# CY8C5888LTI_LP097 register map
File version: 0.1
CY8C58LP
Registers are 8-bit, read-write, no defined reset value unless marked. A register's access mark holds for its fields unless they carry their own. Offsets are from the block's base; lines under a group give offsets from that group; [hi:lo] are bit positions; {n}, {i} and the like mark numbered series; 'fields as' and 'values as' point back to an identical list; <NAME> marks a mode.

## Memory map
0x00000000 Counter_2
0x00000000 SleepTimer_1
0x00000000 LED_Reset
0x00000000 Control_Reset
0x00000000 Control_Reg_1
0x00000000 Counter_1
0x00000000 Control_Timer_Reset
0x00000000 Timer_1

## Counter_2
Base 0x00000000
0x40006401 Counter_2_COUNTER — UDB.A0 - Current Counter Value
0x40006421 Counter_2_PERIOD — UDB.D0 - Assigned Period
0x40006431 Counter_2_COMPARE — UDB.D1 - Assigned Compare Value
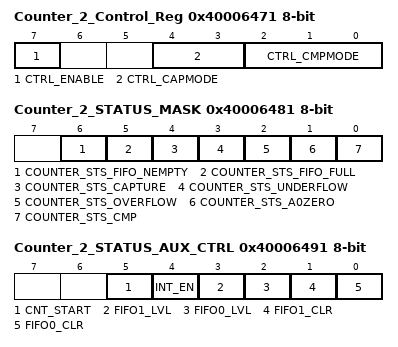
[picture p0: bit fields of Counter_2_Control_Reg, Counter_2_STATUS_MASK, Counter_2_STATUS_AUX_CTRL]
0x40006471 Counter_2_Control_Reg — UDB Control Register - Assigned Control Register Value
  [7] CTRL_ENABLE — Enable Counter
  [4:3] CTRL_CAPMODE — Capture mode
  [2:0] CTRL_CMPMODE — Compare mode
0x40006481 Counter_2_STATUS_MASK — UDB Status bits Interrupt Mask Enable Register
  [6] COUNTER_STS_FIFO_NEMPTY — FIFO Not Empty Status
  [5] COUNTER_STS_FIFO_FULL — FIFO Full Status
  [4] COUNTER_STS_CAPTURE — Capture Status
  [3] COUNTER_STS_UNDERFLOW — Underflow status
  [2] COUNTER_STS_OVERFLOW — Overflow status
  [1] COUNTER_STS_A0ZERO — A0 Zero ouput status
  [0] COUNTER_STS_CMP — Compare output status
0x40006491 Counter_2_STATUS_AUX_CTRL — UDB Auxilliary Control Register
  [5] CNT_START — FIFO0 clear
    0=E_CNT_START0 (Disable counter); 1=E_CNT_START1 (Enable counter)
  [4] INT_EN
    0=E_INT_EN0 (Interrupt disabled); 1=E_INT_EN1 (Interrupt enabled)
  [3] FIFO1_LVL — FIFO level
    0=E_FIFO_LVL_0 (FIFO LVL: input mode: FIFO not full; output mode: FIFO not empty); 1=E_FIFO_LVL_1 (FIFO LVL: input mode: FIFO at least 1/2 empty; output mode: FIFO at least 1/2 full)
  [2] FIFO0_LVL — FIFO level
    values as FIFO1_LVL
  [1] FIFO1_CLR — FIFO1 clear
    0=E_FIFO_CLR_0 (Normal FIFO operation); 1=E_FIFO_CLR_1 (Clear FIFO state)
  [0] FIFO0_CLR — FIFO0 clear
    values as FIFO1_CLR

## SleepTimer_1
Base 0x00000000
0x40004381 SleepTimer_1_CTW_INTERVAL_REG — Timewheel Configuration Register 1
  [3:0] ctw_interval — Sets the central timewheel interval.
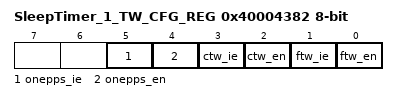
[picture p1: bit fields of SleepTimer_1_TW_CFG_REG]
0x40004382 SleepTimer_1_TW_CFG_REG — Timewheel Configuration Register 2
  [5] onepps_ie — When set and one pulse-per-second is enabled, an interrupt is issued when the pulse occurs.
    1=Enabled (One PPS interrupt is enabled); 0=Disabled (One PPS interrupt is disabled)
  [4] onepps_en — When set, the system returns to the active global power mode once every second.
    1=Enabled (One PPS is enabled); 0=Disabled (One PPS is disabled)
  [3] ctw_ie — When set and the central timewheel is enabled, an interrupt is issued when the central timewheel reaches the selected interval.
    1=Enabled (CTW interrupt is enabled); 0=Disabled (CTW interrupt is disabled)
  [2] ctw_en — When set, the system returns to the active global power mode when the central timewheel reaches the selected interval.
    1=Enabled (CTW is enabled); 0=Disabled (CTW is disabled)
  [1] ftw_ie — When set and the fast timewheel is enabled, an interrupt is issued when it reaches the terminal count.
    1=Enabled (FTW interrupt is enabled); 0=Disabled (FTW interrupt is disabled)
  [0] ftw_en — When set, the system returns to the active global power mode when the fast timewheel reaches the selected interval.
    1=Enabled (FTW is enabled); 0=Disabled (FTW is disabled)

## LED_Reset
Base 0x00000000
0x40006470 LED_Reset_CONTROL_REG

## Control_Reset
Base 0x00000000
0x40006474 Control_Reset_CONTROL_REG

## Control_Reg_1
Base 0x00000000
0x40006475 Control_Reg_1_CONTROL_REG

## Counter_1
Base 0x00000000
0x40006400 Counter_1_COUNTER — UDB.A0 - Current Counter Value
0x40006420 Counter_1_PERIOD — UDB.D0 - Assigned Period
0x40006430 Counter_1_COMPARE — UDB.D1 - Assigned Compare Value
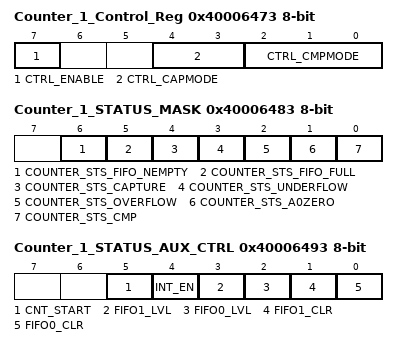
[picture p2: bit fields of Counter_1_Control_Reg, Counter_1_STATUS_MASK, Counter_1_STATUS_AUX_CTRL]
0x40006473 Counter_1_Control_Reg — UDB Control Register - Assigned Control Register Value
  [7] CTRL_ENABLE — Enable Counter
  [4:3] CTRL_CAPMODE — Capture mode
  [2:0] CTRL_CMPMODE — Compare mode
0x40006483 Counter_1_STATUS_MASK — UDB Status bits Interrupt Mask Enable Register
  fields as Counter_2.Counter_2_STATUS_MASK
0x40006493 Counter_1_STATUS_AUX_CTRL — UDB Auxilliary Control Register
  fields as Counter_2.Counter_2_STATUS_AUX_CTRL

## Control_Timer_Reset
Base 0x00000000
0x40006472 Control_Timer_Reset_CONTROL_REG

## Timer_1
Base 0x00000000
0x40006402 Timer_1_COUNTER 24-bit — UDB.A0 - Current Down Counter Value
0x40006422 Timer_1_PERIOD 24-bit — UDB.D0 - Assigned Period
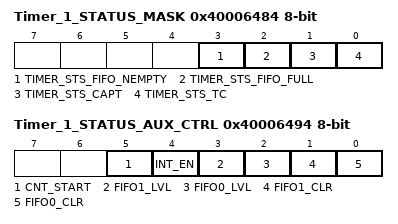
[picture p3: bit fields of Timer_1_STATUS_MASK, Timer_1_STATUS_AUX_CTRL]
0x40006484 Timer_1_STATUS_MASK — UDB Status bits Interrupt Mask Enable Register
  [3] TIMER_STS_FIFO_NEMPTY ro — FIFO Empty status
  [2] TIMER_STS_FIFO_FULL ro — FIFO Full Status
  [1] TIMER_STS_CAPT ro — Enables the Interrupt on Capture
  [0] TIMER_STS_TC ro — Enables the Interrupt on TC
0x40006494 Timer_1_STATUS_AUX_CTRL — UDB Auxilliary Control Register
  fields as Counter_2.Counter_2_STATUS_AUX_CTRL
